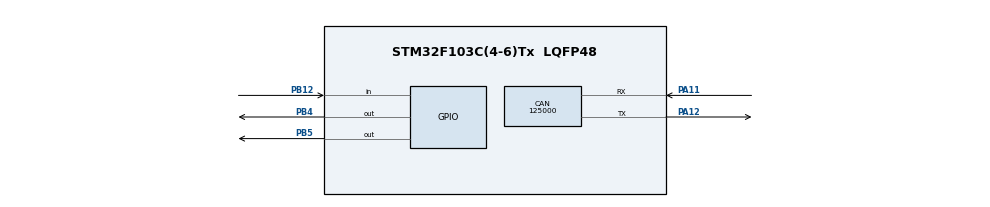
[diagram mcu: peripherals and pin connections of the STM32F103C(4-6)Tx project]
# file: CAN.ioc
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CAN.BS1=CAN_BS1_2TQ
CAN.CalculateBaudRate=125000
CAN.CalculateTimeBit=8000
CAN.CalculateTimeQuantum=2000.0
Mcu.Family=STM32F1
Mcu.Name=STM32F103C(4-6)Tx
Mcu.Package=LQFP48
NVIC.PriorityGroup=NVIC_PRIORITYGROUP_4
NVIC.USB_HP_CAN1_TX_IRQn=true\:0\:0\:false\:false\:true\:true\:true\:true
NVIC.USB_LP_CAN1_RX0_IRQn=true\:0\:0\:false\:false\:true\:true\:true\:true
PA11.GPIO_PuPd=GPIO_NOPULL
PA11.Mode=CAN_Activate
PA11.Signal=CAN_RX
PA12.Mode=CAN_Activate
PA12.Signal=CAN_TX
PA13.Mode=Serial_Wire
PA13.Signal=SYS_JTMS-SWDIO
PA14.Mode=Serial_Wire
PA14.Signal=SYS_JTCK-SWCLK
PB12.GPIO_PuPd=GPIO_PULLUP
PB12.Signal=GPIO_Input
PB4.Signal=GPIO_Output
PB5.Signal=GPIO_Output
ProjectManager.HeapSize=0x200
ProjectManager.StackSize=0x400
ProjectManager.TargetToolchain=STM32CubeIDE
RCC.APB1Freq_Value=8000000
RCC.APB2Freq_Value=8000000
board=custom

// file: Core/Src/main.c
/* USER CODE BEGIN Header */
/**
  ******************************************************************************
  * @file           : main.c
  * @brief          : Main program body
  ******************************************************************************
  * @attention
  *
  * Copyright (c) 2025 STMicroelectronics.
  * All rights reserved.
  *
  * This software is licensed under terms that can be found in the LICENSE file
  * in the root directory of this software component.
  * If no LICENSE file comes with this software, it is provided AS-IS.
  *
  ******************************************************************************
  */
/* USER CODE END Header */
#include "main.h"

/* USER CODE BEGIN Includes */
#include "CAN.h"
/* USER CODE END Includes */

CAN_HandleTypeDef hcan;

void SystemClock_Config(void);
static void MX_GPIO_Init(void);
static void MX_CAN_Init(void);

int main(void)
{

  /* MCU Configuration--------------------------------------------------------*/

  /* Reset of all peripherals, Initializes the Flash interface and the Systick. */
  HAL_Init();

  /* Configure the system clock */
  SystemClock_Config();

  /* Initialize all configured peripherals */
  MX_GPIO_Init();
  MX_CAN_Init();
  /* USER CODE BEGIN 2 */
ancit_can_start();
  /* USER CODE END 2 */

  /* Infinite loop */
  while (1)
  {
	  ancit_can_wait_for_switch_press();
	  HAL_Delay(50);
	  ancit_can_check_for_rx();
  }
}

void SystemClock_Config(void)
{
  RCC_OscInitTypeDef RCC_OscInitStruct = {0};
  RCC_ClkInitTypeDef RCC_ClkInitStruct = {0};

  /** Initializes the RCC Oscillators according to the specified parameters
  * in the RCC_OscInitTypeDef structure.
  */
  RCC_OscInitStruct.OscillatorType = RCC_OSCILLATORTYPE_HSI;
  RCC_OscInitStruct.HSIState = RCC_HSI_ON;
  RCC_OscInitStruct.HSICalibrationValue = RCC_HSICALIBRATION_DEFAULT;
  RCC_OscInitStruct.PLL.PLLState = RCC_PLL_NONE;
  if (HAL_RCC_OscConfig(&RCC_OscInitStruct) != HAL_OK)
  {
    Error_Handler();
  }

  /** Initializes the CPU, AHB and APB buses clocks
  */
  RCC_ClkInitStruct.ClockType = RCC_CLOCKTYPE_HCLK|RCC_CLOCKTYPE_SYSCLK
                              |RCC_CLOCKTYPE_PCLK1|RCC_CLOCKTYPE_PCLK2;
  RCC_ClkInitStruct.SYSCLKSource = RCC_SYSCLKSOURCE_HSI;
  RCC_ClkInitStruct.AHBCLKDivider = RCC_SYSCLK_DIV1;
  RCC_ClkInitStruct.APB1CLKDivider = RCC_HCLK_DIV1;
  RCC_ClkInitStruct.APB2CLKDivider = RCC_HCLK_DIV1;

  if (HAL_RCC_ClockConfig(&RCC_ClkInitStruct, FLASH_LATENCY_0) != HAL_OK)
  {
    Error_Handler();
  }
}

static void MX_CAN_Init(void)
{

  hcan.Instance = CAN1;
  hcan.Init.Prescaler = 16;
  hcan.Init.Mode = CAN_MODE_NORMAL;
  hcan.Init.SyncJumpWidth = CAN_SJW_1TQ;
  hcan.Init.TimeSeg1 = CAN_BS1_2TQ;
  hcan.Init.TimeSeg2 = CAN_BS2_1TQ;
  hcan.Init.TimeTriggeredMode = DISABLE;
  hcan.Init.AutoBusOff = DISABLE;
  hcan.Init.AutoWakeUp = DISABLE;
  hcan.Init.AutoRetransmission = DISABLE;
  hcan.Init.ReceiveFifoLocked = DISABLE;
  hcan.Init.TransmitFifoPriority = DISABLE;
  if (HAL_CAN_Init(&hcan) != HAL_OK)
  {
    Error_Handler();
  }

}

static void MX_GPIO_Init(void)
{
  GPIO_InitTypeDef GPIO_InitStruct = {0};

  /* GPIO Ports Clock Enable */
  __HAL_RCC_GPIOB_CLK_ENABLE();
  __HAL_RCC_GPIOA_CLK_ENABLE();

  /*Configure GPIO pin Output Level */
  HAL_GPIO_WritePin(GPIOB, GPIO_PIN_4|GPIO_PIN_5, GPIO_PIN_RESET);

  /*Configure GPIO pin : PB12 */
  GPIO_InitStruct.Pin = GPIO_PIN_12;
  GPIO_InitStruct.Mode = GPIO_MODE_INPUT;
  GPIO_InitStruct.Pull = GPIO_PULLUP;
  HAL_GPIO_Init(GPIOB, &GPIO_InitStruct);

  /*Configure GPIO pins : PB4 PB5 */
  GPIO_InitStruct.Pin = GPIO_PIN_4|GPIO_PIN_5;
  GPIO_InitStruct.Mode = GPIO_MODE_OUTPUT_PP;
  GPIO_InitStruct.Pull = GPIO_NOPULL;
  GPIO_InitStruct.Speed = GPIO_SPEED_FREQ_LOW;
  HAL_GPIO_Init(GPIOB, &GPIO_InitStruct);

}

void Error_Handler(void)
{
  __disable_irq();
  while (1)
  {
  }
}
